# S32K324_M7 register map
Vendor: NXP Semiconductors; File version: 1.1
CPU: CM7 r0p1, little endian, MPU, FPU, VTOR, 4 interrupt priority bits
Registers are 32-bit, read-write, reset 0x0 unless marked. A register's access mark holds for its fields unless they carry their own. Offsets are from the block's base; [hi:lo] are bit positions; {n}, {i} and the like mark numbered series; 'fields as' and 'values as' point back to an identical list.

## DCM_GPR (part 1 of 2)
Base 0x402AC000; alternate view of DCM
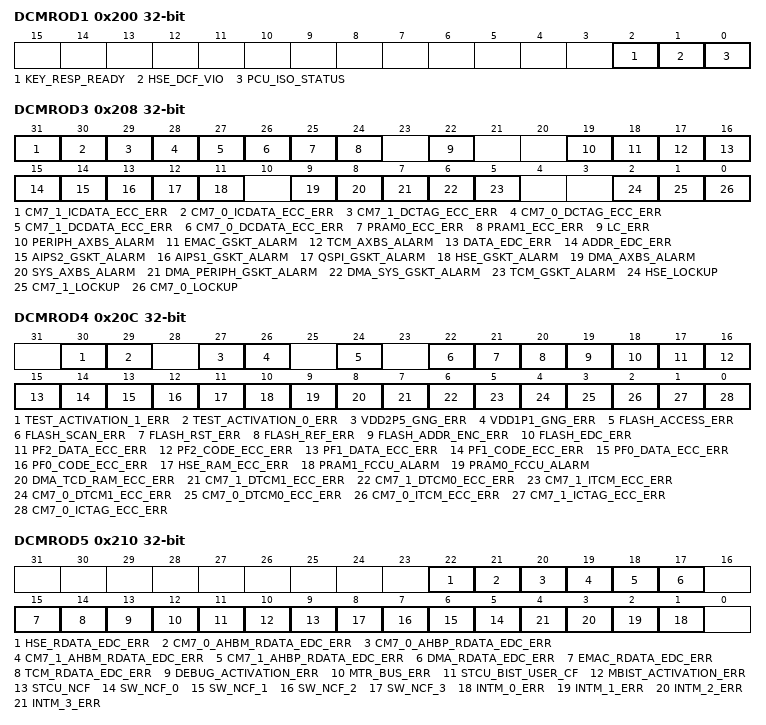
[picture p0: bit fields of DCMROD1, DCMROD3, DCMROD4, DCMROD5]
0x200 DCMROD1 write-1-clears — Read Only GPR On Destructive Reset Register
  [2] KEY_RESP_READY write-1-clears — Key Response Ready
    0=Key response is not ready; 1=Key response is ready
  [1] HSE_DCF_VIO write-1-clears — DCF violation from HSE
    0=No violation from HSE DCF records while decoding; 1=Violation from HSE DCF records while decoding
  [0] PCU_ISO_STATUS write-1-clears — PCU Input Isolation status on previous standby entry
    0=Input isolation did not get enabled in the previous standby entry; 1=Input isolation enabled in the previous standby entry
0x208 DCMROD3 write-1-clears — Read Only GPR On Destructive Reset Register
  [31] CM7_1_ICDATA_ECC_ERR write-1-clears — Multi bit ECC error from CM7_1 ICache data memory
    0=No multi-bit ECC error; 1=Multi-bit ECC error
  [30] CM7_0_ICDATA_ECC_ERR write-1-clears — Multi bit ECC error from CM7_0 ICache data memory
    0=CM7_1 core not in lockup state; 1=CM7_1 core in lockup state
  [29] CM7_1_DCTAG_ECC_ERR write-1-clears — Multi bit ECC error from CM7_1 DCache tag memory
    0=No multi-bit ECC error; 1=Multi-bit ECC error
  [28] CM7_0_DCTAG_ECC_ERR write-1-clears — Multi bit ECC error from CM7_0 DCache tag memory. Read this bit to identify the reason of fault in case of FCCU NCF 2.
    0=No multi-bit ECC error; 1=Multi-bit ECC error
  [27] CM7_1_DCDATA_ECC_ERR write-1-clears — Multi bit ECC error from CM7_1 DCache data memory
    0=No multi-bit ECC error; 1=Multi-bit ECC error
  [26] CM7_0_DCDATA_ECC_ERR write-1-clears — Multi bit ECC error from CM7_0 DCache data memory
    0=No multi-bit ECC error; 1=Multi-bit ECC error
  [25] PRAM0_ECC_ERR write-1-clears — Multi bit ECC error from SRAM0
    0=No multi-bit ECC error; 1=Multi-bit ECC error
  [24] PRAM1_ECC_ERR write-1-clears — Multi bit ECC error from SRAM1
    0=No multi-bit ECC error; 1=Multi-bit ECC error
  [22] LC_ERR write-1-clears — Error in Lifecycle Scanning. Read this bit to identify the reason of fault in case of FCCU NCF 3.
    0=No error while lifecycle scanning; 1=Error while lifecycle scanning
  [19] PERIPH_AXBS_ALARM write-1-clears — PERIPH AXBS_Lite Safety Alarm Status. Read this bit to identify the reason of fault in case of FCCU NCF 1.
    0=No safety alarm indicated by Periph AXBS_Lite; 1=Safety alarm indicated by Periph AXBS_Lite
  [18] EMAC_GSKT_ALARM write-1-clears — EMAC IAHB Gasket Alarm Status. Read this bit to identify the reason of fault in case of FCCU NCF 1.
    0=No alarm indicated by EMAC IAHB gasket; 1=Alarm indicated by EMAC IAHB gasket
  [17] TCM_AXBS_ALARM write-1-clears — TCM AHB Splitter Safety Alarm Status. Read this bit to identify the reason of fault in case of FCCU NCF 1.
    0=No safety alarm indicated by TCM AHB splitter; 1=Safety alarm indicated by TCM AHB splitter
  [16] DATA_EDC_ERR write-1-clears — Status of integrity error on data for safety
    0=No integrity error on data; 1=Data integrity error
  [15] ADDR_EDC_ERR write-1-clears — Status of integrity error on address for safety
    0=No integrity error on address; 1=Address integrity error
  [14] AIPS2_GSKT_ALARM write-1-clears — AIPS2 IAHB Gasket Alarm Status. Read this bit to identify the reason of fault in case of FCCU NCF 1.
    0=No alarm indicated by AIPS2 IAHB gasket; 1=Alarm indicated by AIPS2 IAHB gasket
  [13] AIPS1_GSKT_ALARM write-1-clears — AIPS1 IAHB Gasket Alarm Status. Read this bit to identify the reason of fault in case of FCCU NCF 1.
    0=No alarm indicated by AIPS1 IAHB gasket; 1=Alarm indicated by AIPS1 IAHB gasket
  [12] QSPI_GSKT_ALARM write-1-clears — QSPI IAHB Gasket Alarm Status. Read this bit to identify the reason of fault in case of FCCU NCF 1.
    0=No alarm indicated by QSPI IAHB gasket; 1=Alarm indicated by QSPI IAHB gasket
  [11] HSE_GSKT_ALARM write-1-clears — HSE IAHB Gasket Alarm Status. Read this bit to identify the reason of fault in case of FCCU NCF 1.
    0=No alarm indicated by HSE IAHB gasket; 1=Alarm indicated by HSE IAHB gasket
  [9] DMA_AXBS_ALARM write-1-clears — DMA AXBS_Lite Safety Alarm Status. Read this bit to identify the reason of fault in case of FCCU NCF 1.
    0=No safety alarm indicated by DMA AXBS_Lite; 1=Safety alarm indicated by DMA AXBS_Lite
  [8] SYS_AXBS_ALARM write-1-clears — System AXBS Safety Alarm Status. Read this bit to identify the reason of fault in case of FCCU NCF 1.
    0=No safety alarm indicated by system AXBS; 1=Safety alarm indicated by system AXBS
  [7] DMA_PERIPH_GSKT_ALARM write-1-clears — Status of IAHB gasket safety alarm from DMA periph AXBS IAHB gasket
    0=No safety alarm reported from DMA-periph AXBS IAHB gasket; 1=Safety alarm indicated by DMA-periph AXBS IAHB gasket
  [6] DMA_SYS_GSKT_ALARM write-1-clears — Status of IAHB gasket safety alarm from DMA system AXBS IHAB gasket
    0=No safety alarm reported from DMA-system AXBS IAHB gasket; 1=Safety alarm indicated by DMA-system AXBS IAHB gasket
  [5] TCM_GSKT_ALARM write-1-clears — TCM IAHB Gasket Monitor Alarm Status. Read this bit to identify the reason of fault in case of FCCU NCF 1.
    0=No alarm reported from TCM IAHB gasket; 1=Monitor alarm reported from TCM IAHB gasket
  [2] HSE_LOCKUP write-1-clears — HSE Core Lockup Status. Read this bit to identify the reason of fault in case of FCCU NCF 0.
    0=HSE core not in lockup state; 1=HSE core in lockup state
  [1] CM7_1_LOCKUP write-1-clears — CM7_1 Core Lockup Status. Read this bit to identify the reason of fault in case of FCCU NCF 0.
    values as CM7_0_ICDATA_ECC_ERR
  [0] CM7_0_LOCKUP write-1-clears — CM7_0 Core Lockup Status. Read this bit to identify the reason of fault in case of FCCU NCF 0.
    0=CM7_0 core not in lockup state; 1=CM7_0 core in lockup state
0x20C DCMROD4 write-1-clears — Read Only GPR On Destructive Reset Register
  [30] TEST_ACTIVATION_1_ERR write-1-clears — Accidental Partial Test Activation. Read this bit to identify the reason of fault in case of FCCU NCF 5.
    0=No partial test activated accidentally; 1=Partial test activated accidentally
  [29] TEST_ACTIVATION_0_ERR write-1-clears — Accidental Partial Test Activation. Read this bit to identify the reason of fault in case of FCCU NCF 5.
    values as TEST_ACTIVATION_1_ERR
  [27] VDD2P5_GNG_ERR write-1-clears — Go/no-go for VDD_HV_FLA (double bond) going to FXOSC and PLL
    0=Go indication referring to the supply being clean; 1=No-go indication referring to the supply being unclean and a fault in double bond connection or its routing within the chip
  [26] VDD1P1_GNG_ERR write-1-clears — Go/no-go indicator for VDD1PD1 (double bond) supply going to PLL
    values as VDD2P5_GNG_ERR
  [24] FLASH_ACCESS_ERR write-1-clears — Transaction Monitor Mismatch Error From Flash Controller
    0=No transaction monitor mismatch error from flash controller; 1=Transaction monitor mismatch error from flash controller
  [22] FLASH_SCAN_ERR write-1-clears — Error while DCM flash scanning process due to invalid data
    0=No error while DCM flash scanning; 1=Error while DCM flash scanning
  [21] FLASH_RST_ERR write-1-clears — Flash Reset Error Status
    0=No flash reset error indicated; 1=Flash reset error indicated
  [20] FLASH_REF_ERR write-1-clears — Flash reference current loss or read voltage error while prevoius read(s)
    0=No reference current loss or read voltage error while previous reads(s); 1=Reference current loss or read voltage error while previous read(s)
  [19] FLASH_ADDR_ENC_ERR write-1-clears — Flash Address Encode Error
    0=No address encode error in flash; 1=Address enocde error in flash
  [18] FLASH_EDC_ERR write-1-clears — Status of flash ECC correction error through EDC reported by FMU
    0=No EDC after ECC error reported in flash; 1=EDC after ECC error reported in flash
  [17] PF2_DATA_ECC_ERR write-1-clears — Flash2 Data ECC Uncorrectable Error
    0=No uncorrectable error reported in flash controller port 2 data memory by FMU; 1=Uncorrectable error reported in flash controller port 2 data memory by FMU
  [16] PF2_CODE_ECC_ERR write-1-clears — Flash2 Code ECC Uncorrectable Error
    0=No uncorrectable error reported in flash controller port 2 code memory by FMU; 1=Uncorrectable error reported in flash controller port 2 code memory by FMU
  [15] PF1_DATA_ECC_ERR write-1-clears — Flash1 Data ECC Uncorrectable Error
    0=No uncorrectable error reported in flash controller port 1 data memory by FMU; 1=Uncorrectable error reported in flash controller port 1 data memory by FMU
  [14] PF1_CODE_ECC_ERR write-1-clears — Flash1 Code ECC Uncorrectable Error
    0=No uncorrectable error reported in flash controller port 1 code memory by FMU; 1=Uncorrectable error reported in flash controller port 1 code memory by FMU
  [13] PF0_DATA_ECC_ERR write-1-clears — Flash0 Data ECC Uncorrectable Error
    0=No uncorrectable error reported in flash controller port 0 data memory by FMU; 1=Uncorrectable error reported in flash controller port 0 data memory by FMU
  [12] PF0_CODE_ECC_ERR write-1-clears — Flash0 Code ECC Uncorrectable Error
    0=No uncorrectable error reported in flash controller port 0 code memory by FMU; 1=Uncorrectable error reported in flash controller port 0 code memory by FMU
  [11] HSE_RAM_ECC_ERR write-1-clears — HSE RAM Uncorrectable ECC Status. Read this bit to identify the reason of fault in case of FCCU NCF 2.
    0=No uncorrectable ECC reported by HSE RAM; 1=Uncorrectable ECC reported by HSE RAM
  [10] PRAM1_FCCU_ALARM write-1-clears — Status of PRAM1 safety alarm
    0=No safety alarm indicated by PRAM1; 1=Safety alarm indicated by PRAM1
  [9] PRAM0_FCCU_ALARM write-1-clears — Status of PRAM0 safety alarm
    0=No safety alarm indicated by PRAM0; 1=Safety alarm indicated by PRAM0
  [8] DMA_TCD_RAM_ECC_ERR write-1-clears — Uncorrectable ECC error reported from DMA_TCD memory
    0=No uncorrectable ECC error detected; 1=Uncorrectable ECC error detected
  [7] CM7_1_DTCM1_ECC_ERR write-1-clears — Uncorrectable ECC error reported from CM7_1 Data TCM memory block 1
    values as DMA_TCD_RAM_ECC_ERR
  [6] CM7_1_DTCM0_ECC_ERR write-1-clears — Uncorrectable ECC error reported from CM7_1 Data TCM memory block 0
    values as DMA_TCD_RAM_ECC_ERR
  [5] CM7_1_ITCM_ECC_ERR write-1-clears — Uncorrectable ECC error reported from CM7_1 Instruction TCM memory
    values as DMA_TCD_RAM_ECC_ERR
  [4] CM7_0_DTCM1_ECC_ERR write-1-clears — Uncorrectable ECC error reported from CM7_0 Data TCM memory block 1
    values as DMA_TCD_RAM_ECC_ERR
  [3] CM7_0_DTCM0_ECC_ERR write-1-clears — Uncorrectable ECC error reported from CM7_0 Data TCM memory block 0
    values as DMA_TCD_RAM_ECC_ERR
  [2] CM7_0_ITCM_ECC_ERR write-1-clears — Uncorrectable ECC error reported from CM7_0 Instruction TCM memory
    values as DMA_TCD_RAM_ECC_ERR
  [1] CM7_1_ICTAG_ECC_ERR write-1-clears — Multi bit ECC error from CM7_1 ICache tag memory
    0=No multi-bit ECC error; 1=Multi-bit ECC error
  [0] CM7_0_ICTAG_ECC_ERR write-1-clears — Multi bit ECC error from CM7_0 ICache tag memory
    0=No multi-bit ECC error; 1=Multi-bit ECC error
0x210 DCMROD5 write-1-clears — Read Only GPR On Destructive Reset Register
  [22] HSE_RDATA_EDC_ERR write-1-clears — Integrity (EDC) error on HSE read data for safety
    0=No integrity error reported on HSE read data; 1=Integrity error reported on HSE read data
  [21] CM7_0_AHBM_RDATA_EDC_ERR write-1-clears — Integrity error on CM7_0 main read data for safety
    0=No integrity error reported on CM7_0 main read data; 1=Integrity error reported on CM7_0 main read data
  [20] CM7_0_AHBP_RDATA_EDC_ERR write-1-clears — Integrity error on CM7_0 peripheral read data for safety
    0=No integrity error reported on CM7_0 peripheral read data; 1=Integrity error reported on CM7_0 peripheral read data
  [19] CM7_1_AHBM_RDATA_EDC_ERR write-1-clears — Integrity error on CM7_1 main read data for safety
    0=No integrity error reported on CM7_1 main read data; 1=Integrity error reported on CM7_1 main read data
  [18] CM7_1_AHBP_RDATA_EDC_ERR write-1-clears — Integrity error on CM7_1 peripheral read data for safety
    0=No integrity error reported on CM7_1 peripheral read data; 1=Integrity error reported on CM7_1 peripheral read data
  [17] DMA_RDATA_EDC_ERR write-1-clears — Integrity(EDC) error on eDMA read data for safety
    0=No integrity error reported on eDMA read data; 1=Integrity error reported on eDMA read data
  [15] EMAC_RDATA_EDC_ERR write-1-clears — Integrity(EDC) error on EMAC read data for safety
    0=No integrity error reported on EMAC read data; 1=Integrity error reported on EMAC read data
  [14] TCM_RDATA_EDC_ERR write-1-clears — Integrity(EDC) error on TCM read data for safety
    0=No integrity error reported on TCM read data; 1=Integrity error reported on TCM read data
  [13] DEBUG_ACTIVATION_ERR write-1-clears — Monitoring of unintended debug activation
    0=Unintended debug not activated; 1=Unintended debug activated
  [12] MTR_BUS_ERR write-1-clears — Fault reported due to illegal access on MTR
    0=No transfer error indicated from MTR; 1=Transfer error indicated from MTR
  [11] STCU_BIST_USER_CF write-1-clears — L/M BIST enabled accidentally
    0=No accidental L/M BIST enabled; 1=Accidental L/M BIST enabled
  [10] MBIST_ACTIVATION_ERR write-1-clears — Indicates an accidental backdoor access on memories
    0=No accidental backdoor enabled on memories; 1=Accidental backdoor enabled on memories
  [9] STCU_NCF write-1-clears — STCU non-critical fault, that is, BIST result error
    0=STCU non-critical fault not reported; 1=STCU non-critical fault reported
  [n+5] SW_NCF_{n} write-1-clears (n=0..3) — Software NCF{n} Status
    0=Software NCF{n}, DCMRWF1[FCCU_SW_NCF{n}] not enabled by software; 1=Software NCF{n}, DCMRWF1[FCCU_SW_NCF{n}] enabled by software
  [n+1] INTM_{n}_ERR write-1-clears (n=0..3) — Interrupt monitor{n} error reported by INTM
    0=No error reported by interrupt monitor {n}; 1=Error reported by interrupt monitor {n}
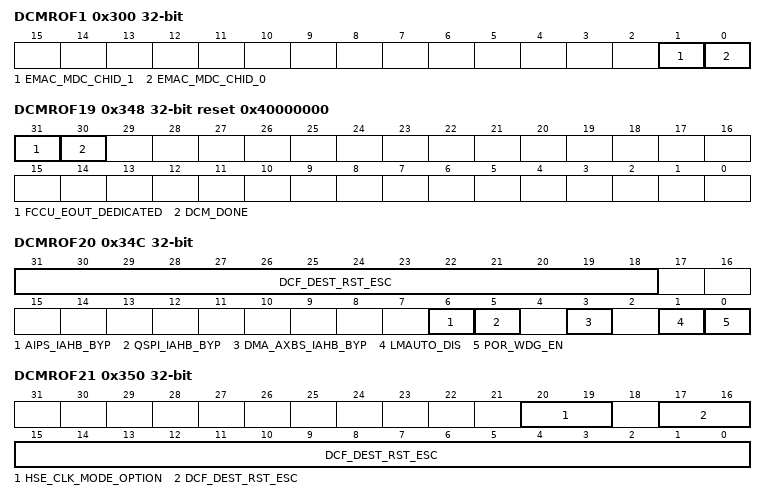
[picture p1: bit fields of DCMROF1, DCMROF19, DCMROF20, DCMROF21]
0x300 DCMROF1 write-1-clears — Read Only GPR On Functional Reset Register
  [1] EMAC_MDC_CHID_1 write-1-clears — EMAC DMA Channel ID1 Status
    0=Channel ID1 is not the current transfer channel ID; 1=Channel ID1 is the current transfer channel ID
  [0] EMAC_MDC_CHID_0 write-1-clears — EMAC DMA Channel ID0 Status
    0=Channel ID0 is not the current transfer channel ID; 1=Channel ID0 is the current transfer channel ID
{0x2FC+4i} DCMROF{i} write-1-clears (i=2..17) — Read Only GPR On Functional Reset Register
  [31:0] DCF_SDID{i-2} write-1-clears — Configuration bits of DCF client SDID {i-2}.
0x348 DCMROF19 ro reset 0x40000000 — Read Only GPR On Functional Reset Register
  [31] FCCU_EOUT_DEDICATED
    0=FCCU_EOUT pins on GPIO2 and GPIO3 acts as general purpose pins supporting all functions; 1=FCCU_EOUT pins on GPIO2 and GPIO3 acts as dedicated EOUT pins
  [30] DCM_DONE
    0=Flash scanning by DCM not complete; 1=Flash scanning completed by DCM
0x34C DCMROF20 ro (reset mask 0x3FF94) — Read Only GPR On Functional Reset Register
  [31:18] DCF_DEST_RST_ESC — This register indicates the information of chip destructive reset escalation support for destructive reset sources as configured in DCF record, DEST_RST_ESC[13:0]
    0=Destructive Reset Escalation disabled; 1=Destructive Reset Escalation enabled
  [6] AIPS_IAHB_BYP — Status of AIPS1/2 IAHB gasket as configured in DCF record, UTEST_MISC[AIPS_IAHB_BYP].
    0=Register wall enabled; 1=Register wall bypassed
  [5] QSPI_IAHB_BYP — Status of QSPI IAHB gasket as configured in DCF record, UTEST_MISC[QSPI_IAHB_BYP].
    0=Register wall enabled; 1=Register wall bypassed
  [3] DMA_AXBS_IAHB_BYP — Status of DMA AXBS IAHB gasket as configured in DCF record, UTEST_MISC[DMA_AXBS_IAHB_BYP].
    0=Register wall enabled; 1=Register wall bypassed
  [1] LMAUTO_DIS — PMC last mile automatic croosover from boot regulationfeature support.
    0=Last mile auto crossover feautre is supported for the chip; 1=Last mile auto crossover feautre is not supported for the chip
  [0] POR_WDG_EN — Indicates the status of POR_WDG as configured in DCF record, UTEST_MISC[POR_WDG_EN].
    0=POR Watchdog Disabled; 1=POR Watchdog Enabled (default)
0x350 DCMROF21 ro — Read Only GPR On Functional Reset Register
  [20:19] HSE_CLK_MODE_OPTION — HSE Clock Mode Option
    0=Applicable for clocking option A. Ratio of 1:2 in between HSE IPS interface clock (AIPS_SLOW_CLK) and HSE module clock (HSE_CLK), HSE_IAHB gasket enabled.; 1=Applicable for clocking option C, D, E, E2, and F. Ratio of 1:2 in between HSE IPS interface clock (AIPS_SLOW_CLK) and HSE module clock (HSE_CLK), HSE_IAHB gasket bypass.; 2=10b and 11b both are applicable for clocking option B in same way. Ratio of 1:4 in between HSE IPS interface clock (AIPS_SLOW_CLK) and HSE module clock (HSE_CLK), HSE_IAHB gasket enabled.; 3=10b and 11b both are applicable for clocking option B in same way. Ratio of 1:4 in between HSE IPS interface clock (AIPS_SLOW_CLK) and HSE module clock (HSE_CLK), HSE_IAHB gasket enabled.
  [17:0] DCF_DEST_RST_ESC — This register indicates the information of chip destructive reset escalation support for destructive reset sources as configured in DCF record, DEST_RST_ESC[31:14]
    values as DCMROF20.DCF_DEST_RST_ESC
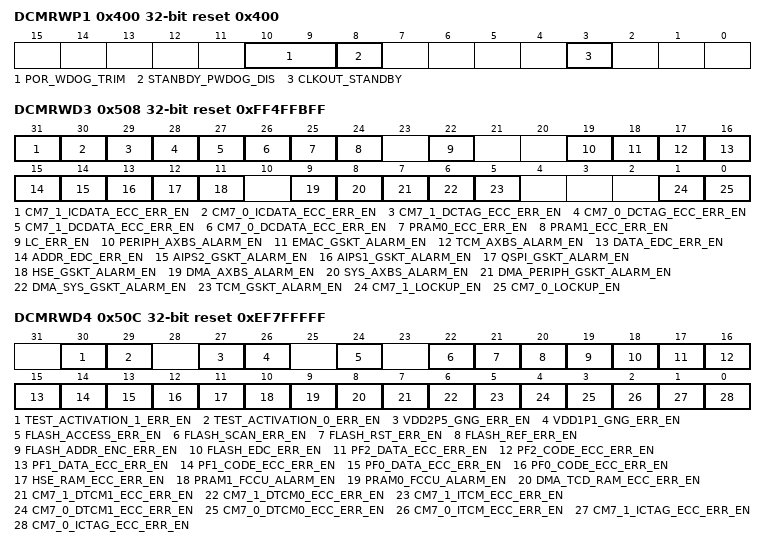
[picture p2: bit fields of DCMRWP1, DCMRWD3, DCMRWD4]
0x400 DCMRWP1 reset 0x400 — Read Write GPR On Power On Reset Register
  [10:9] POR_WDOG_TRIM — Trims for POR WDG timeout value.
  [8] STANBDY_PWDOG_DIS — Disables the standby entry and exit monitoring window of the POR WDOG.
    0=Enabled; 1=Disabled
  [3] CLKOUT_STANDBY — Clockout standby expose over functional and destructive reset.
    0=The CLKOUT_STANDBY function is not available while functional or destructive reset on PTA12; 1=The CLKOUT_STANDBY function is available while functional or destructive reset on PTA12
0x408 DCMRWP3 — Read Write GPR On Power On Reset Register
  [9] DEST_RST9_AS_IPI — Configures a destructive reset to interrupt.
    0=Destructive reset; 1=PLL LOL interrupt
0x504 DCMRWD2 — Read Write GPR On Destructive Reset Register
  [7] EOUT_STAT_DUR_STEST — Controls the EOUT state during selftest.
    0=EOUT state will change to high Z post selftest when device is under reset; 1=EOUT state will remain in FAULT state until this bit is cleared
0x508 DCMRWD3 reset 0xFF4FFBFF — Read Write GPR On Destructive Reset Register
  [31] CM7_1_ICDATA_ECC_ERR_EN — Enable bit for enabling the fault monitoring at FCCU NCF 2 for the fault: Multi bit ECC error from CM7_1 ICache data memory
    0=No multi-bit ECC error; 1=Multi-bit ECC error
  [30] CM7_0_ICDATA_ECC_ERR_EN — Enable bit for enabling the fault monitoring at FCCU NCF 2 for the fault: Multi bit ECC error from CM7_0 ICache data memory
    0=No multi-bit ECC error; 1=Multi-bit ECC error
  [29] CM7_1_DCTAG_ECC_ERR_EN — Enable bit for enabling the fault monitoring at FCCU NCF 2 for the fault: Multi bit ECC error from CM7_1 DCache tag memory
    0=No multi-bit ECC error; 1=Multi-bit ECC error
  [28] CM7_0_DCTAG_ECC_ERR_EN — Enable bit for enabling the fault monitoring at FCCU NCF 2 for the fault: Multi bit ECC error from CM7_0 DCache tag memory
    0=No multi-bit ECC error; 1=Multi-bit ECC error
  [27] CM7_1_DCDATA_ECC_ERR_EN — Enable bit for enabling the fault monitoring at FCCU NCF 2 for the fault: Multi bit ECC error from CM7_1 DCache data memory
    0=No multi-bit ECC error; 1=Multi-bit ECC error
  [26] CM7_0_DCDATA_ECC_ERR_EN — Enable bit for enabling the fault monitoring at FCCU NCF 2 for the fault: Multi bit ECC error from CM7_0 DCache data memory
    0=No multi-bit ECC error; 1=Multi-bit ECC error
  [25] PRAM0_ECC_ERR_EN — Enable bit for enabling the fault monitoring at FCCU NCF 2 for the fault: Multi bit ECC error from SRAM0
    0=No multi-bit ECC error; 1=Multi-bit ECC error
  [24] PRAM1_ECC_ERR_EN — Enable bit for enabling the fault monitoring at FCCU NCF 2 for the fault: Multi bit ECC error from SRAM1
    0=No multi-bit ECC error; 1=Multi-bit ECC error
  [22] LC_ERR_EN — Enable bit for enabling the fault monitoring at FCCU NCF 3 for the fault: Error in lifecycle scanning
    values as DCMROD3.LC_ERR
  [19] PERIPH_AXBS_ALARM_EN — Enable bit for enabling the fault monitoring at FCCU NCF 1 for the fault: PERIPH AXBS_Lite safety alarm
    values as DCMROD3.PERIPH_AXBS_ALARM
  [18] EMAC_GSKT_ALARM_EN — Enable bit for enabling the fault monitoring at FCCU NCF 1 for the fault: EMAC IAHB gasket alarm.
    values as DCMROD3.EMAC_GSKT_ALARM
  [17] TCM_AXBS_ALARM_EN — Enable bit for enabling the fault monitoring at FCCU NCF 1 for the fault: TCM AHB splitter safety alarm
    values as DCMROD3.TCM_AXBS_ALARM
  [16] DATA_EDC_ERR_EN — Enable bit for enabling the fault monitoring at FCCU NCF 1 for the fault: integrity error on data for safety
    0=No integrity error on data; 1=Data integrity error
  [15] ADDR_EDC_ERR_EN — Enable bit for enabling the fault monitoring at FCCU NCF 1 for the fault: integrity error on address for safety
    0=No integrity error on address; 1=Address integrity error
  [14] AIPS2_GSKT_ALARM_EN — Enable bit for enabling the fault monitoring at FCCU NCF 1 for the fault: AIPS2 IAHB gasket alarm.
    values as DCMROD3.AIPS2_GSKT_ALARM
  [13] AIPS1_GSKT_ALARM_EN — Enable bit for enabling the fault monitoring at FCCU NCF 1 for the fault: AIPS1 IAHB gasket alarm.
    values as DCMROD3.AIPS1_GSKT_ALARM
  [12] QSPI_GSKT_ALARM_EN — Enable bit for enabling the fault monitoring at FCCU NCF 1 for the fault: QSPI IAHB gasket alarm.
    values as DCMROD3.QSPI_GSKT_ALARM
  [11] HSE_GSKT_ALARM_EN — Enable bit for enabling the fault monitoring at FCCU NCF 1 for the fault: HSE IAHB gasket alarm.
    values as DCMROD3.HSE_GSKT_ALARM
  [9] DMA_AXBS_ALARM_EN — Enable bit for enabling the fault monitoring at FCCU NCF 1 for the fault: DMA AXBS_Lite safety alarm
    values as DCMROD3.DMA_AXBS_ALARM
  [8] SYS_AXBS_ALARM_EN — Enable bit for enabling the fault monitoring at FCCU NCF 1 for the fault: system AXBS safety alarm.
    values as DCMROD3.SYS_AXBS_ALARM
  [7] DMA_PERIPH_GSKT_ALARM_EN — Enable bit for enabling the fault monitoring at FCCU NCF 1 for the fault: IAHB gasket safety alarm from DMA periph AXBS IAHB gasket
    values as DCMROD3.DMA_PERIPH_GSKT_ALARM
  [6] DMA_SYS_GSKT_ALARM_EN — Enable bit for enabling the fault monitoring at FCCU NCF 1 for the fault: IAHB gasket safety alarm from DMA system AXBS IHAB gasket
    values as DCMROD3.DMA_SYS_GSKT_ALARM
  [5] TCM_GSKT_ALARM_EN — Enable bit for enabling the fault monitoring at FCCU NCF 1 for the fault: TCM IAHB Gasket monitor alarm
    values as DCMROD3.TCM_GSKT_ALARM
  [1] CM7_1_LOCKUP_EN — Enable bit for enabling the fault monitoring at FCCU NCF 0 for the fault: CM7_1 core lockup
    values as DCMROD3.CM7_0_ICDATA_ECC_ERR
  [0] CM7_0_LOCKUP_EN — Enable bit for enabling the fault monitoring at FCCU NCF 0 for the fault: CM7_0 core lockup.
    values as DCMROD3.CM7_0_LOCKUP
0x50C DCMRWD4 reset 0xEF7FFFFF — Read Write GPR On Destructive Reset Register
  [30] TEST_ACTIVATION_1_ERR_EN — Enable bit for enabling the fault monitoring at FCCU NCF 5 for the fault: Accidental partial test activation
    values as DCMROD4.TEST_ACTIVATION_1_ERR
  [29] TEST_ACTIVATION_0_ERR_EN — Enable bit for enabling the fault monitoring at FCCU NCF 5 for the fault: Accidental partial test activation
    values as DCMROD4.TEST_ACTIVATION_1_ERR
  [27] VDD2P5_GNG_ERR_EN — Enable bit for enabling the fault monitoring at FCCU NCF 4 for the fault: Go/Nogo for VDD_HV_FLA (double bond) going to FXOSC and PLL
    0=Go indication referring to the supply being clean; 1=No go indication referring to the supply being unclean and a fault in double bond connection or its routing within the chip
  [26] VDD1P1_GNG_ERR_EN — Enable bit for enabling the fault monitoring at FCCU NCF 4 for the fault: Go/Nogo indicator for VDD1PD1 (double bond) supply going to PLL
    values as VDD2P5_GNG_ERR_EN
  [24] FLASH_ACCESS_ERR_EN — Enable bit for enabling the fault monitoring at FCCU NCF 3 for the fault: Transaction monitor mismatch error from flash controller
    values as DCMROD4.FLASH_ACCESS_ERR
  [22] FLASH_SCAN_ERR_EN — Enable bit for enabling the fault monitoring at FCCU NCF 3 for the fault: Error while DCM flash scanning process due to invalid data
    values as DCMROD4.FLASH_SCAN_ERR
  [21] FLASH_RST_ERR_EN — Enable bit for enabling the fault monitoring at FCCU NCF 3 for the fault: Flash reset error
    values as DCMROD4.FLASH_RST_ERR
  [20] FLASH_REF_ERR_EN — Enable bit for enabling the fault monitoring at FCCU NCF 3 for the fault: Flash reference current loss or read voltage error while prevoius read(s)
    values as DCMROD4.FLASH_REF_ERR
  [19] FLASH_ADDR_ENC_ERR_EN — Enable bit for enabling the fault monitoring at FCCU NCF 3 for the fault: Flash address encode error
    0=No address encode error in flash; 1=Address encode error in flash
  [18] FLASH_EDC_ERR_EN — Enable bit for enabling the fault monitoring at FCCU NCF 3 for the fault: Flash ECC correction error through EDC reported by FMU
    values as DCMROD4.FLASH_EDC_ERR
  [17] PF2_DATA_ECC_ERR_EN — Enable bit for enabling the fault monitoring at FCCU NCF 3 for the fault: Flash2 data ECC uncorrectable error
    values as DCMROD4.PF2_DATA_ECC_ERR
  [16] PF2_CODE_ECC_ERR_EN — Enable bit for enabling the fault monitoring at FCCU NCF 3 for the fault: Flash2 code ECC uncorrectable error
    values as DCMROD4.PF2_CODE_ECC_ERR
  [15] PF1_DATA_ECC_ERR_EN — Enable bit for enabling the fault monitoring at FCCU NCF 3 for the fault: Flash1 data ECC uncorrectable error
    values as DCMROD4.PF1_DATA_ECC_ERR
  [14] PF1_CODE_ECC_ERR_EN — Enable bit for enabling the fault monitoring at FCCU NCF 3 for the fault: Flash1 code ECC uncorrectable error
    values as DCMROD4.PF1_CODE_ECC_ERR
  [13] PF0_DATA_ECC_ERR_EN — Enable bit for enabling the fault monitoring at FCCU NCF 3 for the fault: Flash0 data ECC uncorrectable error
    values as DCMROD4.PF0_DATA_ECC_ERR
  [12] PF0_CODE_ECC_ERR_EN — Enable bit for enabling the fault monitoring at FCCU NCF 3 for the fault: Flash0 code ECC uncorrectable error
    values as DCMROD4.PF0_CODE_ECC_ERR
  [11] HSE_RAM_ECC_ERR_EN — Enable bit for enabling the fault monitoring at FCCU NCF 2 for the fault: HSE RAM Uncorrectable ECC
    values as DCMROD4.HSE_RAM_ECC_ERR
  [10] PRAM1_FCCU_ALARM_EN — Enable bit for enabling the fault monitoring at FCCU NCF 2 for the fault: PRAM1 safety alarm
    values as DCMROD4.PRAM1_FCCU_ALARM
  [9] PRAM0_FCCU_ALARM_EN — Enable bit for enabling the fault monitoring at FCCU NCF 2 for the fault: PRAM0 safety alarm
    values as DCMROD4.PRAM0_FCCU_ALARM
  [8] DMA_TCD_RAM_ECC_ERR_EN — Enable bit for enabling the fault monitoring at FCCU NCF 2 for the fault: Uncorrectable ECC error reported from DMA_TCD memory
    0=Uncorrectable ECC error detection at FCCU not enabled; 1=Uncorrectable ECC error detection enabled at FCCU
  [7] CM7_1_DTCM1_ECC_ERR_EN — Enable bit for enabling the fault monitoring at FCCU NCF 2 for the fault: Uncorrectable ECC error from CM7_1 Data TCM memory block 1
    values as DMA_TCD_RAM_ECC_ERR_EN
  [6] CM7_1_DTCM0_ECC_ERR_EN — Enable bit for enabling the fault monitoring at FCCU NCF 2 for the fault: Uncorrectable ECC error from CM7_1 Data TCM memory block 0
    values as DMA_TCD_RAM_ECC_ERR_EN
  [5] CM7_1_ITCM_ECC_ERR_EN — Enable bit for enabling the fault monitoring at FCCU NCF 2 for the fault: Uncorrectable ECC error from CM7_1 Instruction TCM memory
    values as DMA_TCD_RAM_ECC_ERR_EN
  [4] CM7_0_DTCM1_ECC_ERR_EN — Enable bit for enabling the fault monitoring at FCCU NCF 2 for the fault: Uncorrectable ECC error from CM7_0 Data TCM memory block 1
    values as DMA_TCD_RAM_ECC_ERR_EN
  [3] CM7_0_DTCM0_ECC_ERR_EN — Enable bit for enabling the fault monitoring at FCCU NCF 2 for the fault: Uncorrectable ECC error from CM7_0 Data TCM memory block 0
    values as DMA_TCD_RAM_ECC_ERR_EN
  [2] CM7_0_ITCM_ECC_ERR_EN — Enable bit for enabling the fault monitoring at FCCU NCF 2 for the fault: Uncorrectable ECC error from CM7_0 Instruction TCM memory
    values as DMA_TCD_RAM_ECC_ERR_EN
  [1] CM7_1_ICTAG_ECC_ERR_EN — Enable bit for enabling the fault monitoring at FCCU NCF 2 for the fault: Multi bit ECC error from CM7_1 ICache tag memory
    0=No multi-bit ECC error; 1=Multi-bit ECC error
  [0] CM7_0_ICTAG_ECC_ERR_EN — Enable bit for enabling the fault monitoring at FCCU NCF 2 for the fault: Multi bit ECC error from CM7_0 ICache tag memory
    0=No multi-bit ECC error; 1=Multi-bit ECC error
